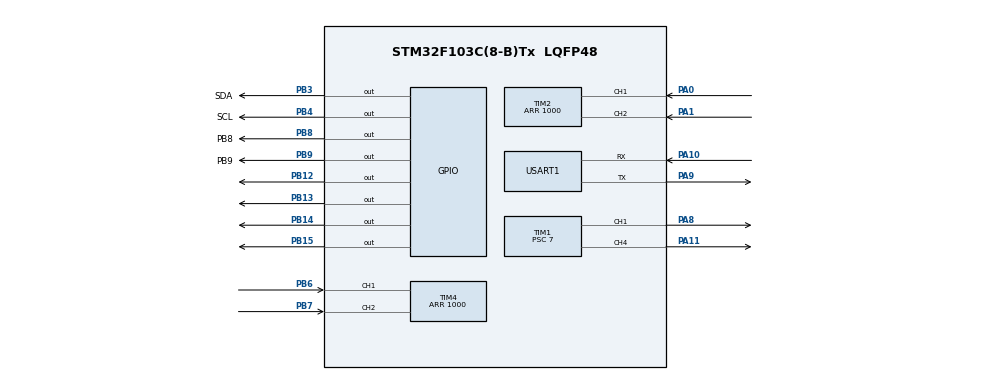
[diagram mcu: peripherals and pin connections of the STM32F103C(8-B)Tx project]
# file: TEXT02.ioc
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Mcu.Family=STM32F1
Mcu.Name=STM32F103C(8-B)Tx
Mcu.Package=LQFP48
NVIC.PriorityGroup=NVIC_PRIORITYGROUP_4
PA0-WKUP.Signal=S_TIM2_CH1_ETR
PA1.Signal=S_TIM2_CH2
PA10.Mode=Asynchronous
PA10.Signal=USART1_RX
PA11.Signal=S_TIM1_CH4
PA13.Mode=Serial_Wire
PA13.Signal=SYS_JTMS-SWDIO
PA14.Mode=Serial_Wire
PA14.Signal=SYS_JTCK-SWCLK
PA8.GPIO_ModeDefaultPP=GPIO_MODE_AF_PP
PA8.Signal=S_TIM1_CH1
PA9.Mode=Asynchronous
PA9.Signal=USART1_TX
PB12.Signal=GPIO_Output
PB13.Signal=GPIO_Output
PB14.Signal=GPIO_Output
PB15.Signal=GPIO_Output
PB3.GPIO_Label=SDA
PB3.GPIO_ModeDefaultOutputPP=GPIO_MODE_OUTPUT_OD
PB3.GPIO_PuPd=GPIO_NOPULL
PB3.GPIO_Speed=GPIO_SPEED_FREQ_HIGH
PB3.PinState=GPIO_PIN_SET
PB3.Signal=GPIO_Output
PB4.GPIO_Label=SCL
PB4.GPIO_ModeDefaultOutputPP=GPIO_MODE_OUTPUT_OD
PB4.GPIO_PuPd=GPIO_NOPULL
PB4.GPIO_Speed=GPIO_SPEED_FREQ_HIGH
PB4.Signal=GPIO_Output
PB6.Signal=S_TIM4_CH1
PB7.Signal=S_TIM4_CH2
PB8.GPIO_Label=PB8
PB8.GPIO_ModeDefaultOutputPP=GPIO_MODE_OUTPUT_OD
PB8.GPIO_PuPd=GPIO_NOPULL
PB8.Signal=GPIO_Output
PB9.GPIO_Label=PB9
PB9.GPIO_ModeDefaultOutputPP=GPIO_MODE_OUTPUT_OD
PB9.GPIO_PuPd=GPIO_NOPULL
PB9.Signal=GPIO_Output
ProjectManager.HeapSize=0x200
ProjectManager.StackSize=0x400
ProjectManager.TargetToolchain=CMake
RCC.APB1Freq_Value=8000000
RCC.APB2Freq_Value=8000000
SH.S_TIM1_CH1.0=TIM1_CH1,PWM Generation1 CH1
SH.S_TIM1_CH4.0=TIM1_CH4,PWM Generation4 CH4
SH.S_TIM2_CH1_ETR.0=TIM2_CH1,Encoder_Interface
SH.S_TIM2_CH2.0=TIM2_CH2,Encoder_Interface
SH.S_TIM4_CH1.0=TIM4_CH1,Encoder_Interface
SH.S_TIM4_CH2.0=TIM4_CH2,Encoder_Interface
TIM1.AutoReloadPreload=TIM_AUTORELOAD_PRELOAD_ENABLE
TIM1.Channel-PWM\ Generation1\ CH1=TIM_CHANNEL_1
TIM1.Channel-PWM\ Generation4\ CH4=TIM_CHANNEL_4
TIM1.Period=1000
TIM1.Prescaler=7
TIM2.AutoReloadPreload=TIM_AUTORELOAD_PRELOAD_ENABLE
TIM2.Period=1000
TIM4.AutoReloadPreload=TIM_AUTORELOAD_PRELOAD_ENABLE
TIM4.Period=1000
USART1.VirtualMode=VM_ASYNC
board=custom

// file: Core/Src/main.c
/* USER CODE BEGIN Header */
/**
  ******************************************************************************
  * @file           : main.c
  * @brief          : Main program body
  ******************************************************************************
  * @attention
  *
  * Copyright (c) 2025 STMicroelectronics.
  * All rights reserved.
  *
  * This software is licensed under terms that can be found in the LICENSE file
  * in the root directory of this software component.
  * If no LICENSE file comes with this software, it is provided AS-IS.
  *
  ******************************************************************************
  */
/* USER CODE END Header */
#include "main.h"
#include "tim.h"
#include "usart.h"
#include "gpio.h"

void SystemClock_Config(void);

int main(void)
{

  /* MCU Configuration--------------------------------------------------------*/

  /* Reset of all peripherals, Initializes the Flash interface and the Systick. */
  HAL_Init();

  /* Configure the system clock */
  SystemClock_Config();

  /* Initialize all configured peripherals */
  MX_GPIO_Init();
  MX_TIM1_Init();
  MX_TIM4_Init();
  MX_TIM2_Init();
  MX_USART1_UART_Init();

  /* Infinite loop */
  /* USER CODE BEGIN WHILE */
  while (1)
  {
    __HAL_TIM_SET_COMPARE(&htim1,TIM_CHANNEL_1,100);
    __HAL_TIM_SET_COMPARE(&htim1,TIM_CHANNEL_4,100);

  }
    /* USER CODE END WHILE */

}

void SystemClock_Config(void)
{
  RCC_OscInitTypeDef RCC_OscInitStruct = {0};
  RCC_ClkInitTypeDef RCC_ClkInitStruct = {0};

  /** Initializes the RCC Oscillators according to the specified parameters
  * in the RCC_OscInitTypeDef structure.
  */
  RCC_OscInitStruct.OscillatorType = RCC_OSCILLATORTYPE_HSI;
  RCC_OscInitStruct.HSIState = RCC_HSI_ON;
  RCC_OscInitStruct.HSICalibrationValue = RCC_HSICALIBRATION_DEFAULT;
  RCC_OscInitStruct.PLL.PLLState = RCC_PLL_NONE;
  if (HAL_RCC_OscConfig(&RCC_OscInitStruct) != HAL_OK)
  {
    Error_Handler();
  }

  /** Initializes the CPU, AHB and APB buses clocks
  */
  RCC_ClkInitStruct.ClockType = RCC_CLOCKTYPE_HCLK|RCC_CLOCKTYPE_SYSCLK
                              |RCC_CLOCKTYPE_PCLK1|RCC_CLOCKTYPE_PCLK2;
  RCC_ClkInitStruct.SYSCLKSource = RCC_SYSCLKSOURCE_HSI;
  RCC_ClkInitStruct.AHBCLKDivider = RCC_SYSCLK_DIV1;
  RCC_ClkInitStruct.APB1CLKDivider = RCC_HCLK_DIV1;
  RCC_ClkInitStruct.APB2CLKDivider = RCC_HCLK_DIV1;

  if (HAL_RCC_ClockConfig(&RCC_ClkInitStruct, FLASH_LATENCY_0) != HAL_OK)
  {
    Error_Handler();
  }
}

void Error_Handler(void)
{
  __disable_irq();
  while (1)
  {
  }
}
